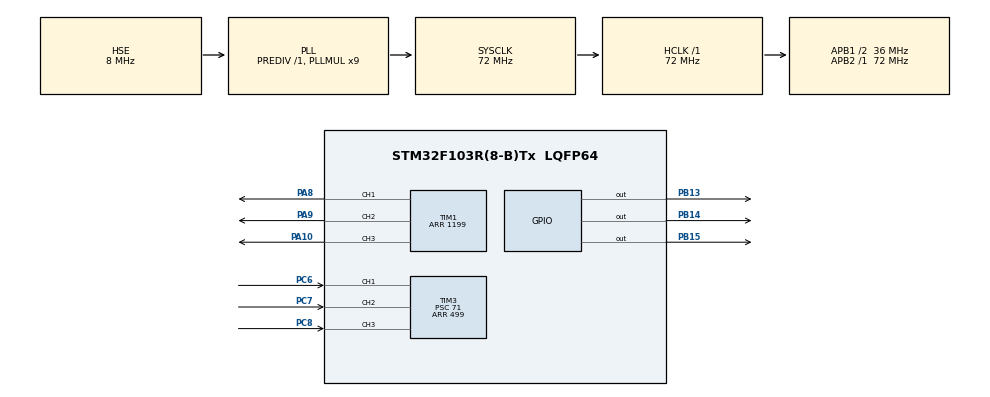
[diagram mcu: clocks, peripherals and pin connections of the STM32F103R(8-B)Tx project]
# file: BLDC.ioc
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Mcu.Family=STM32F1
Mcu.Name=STM32F103R(8-B)Tx
Mcu.Package=LQFP64
NVIC.PriorityGroup=NVIC_PRIORITYGROUP_4
NVIC.TIM3_IRQn=true\:0\:0\:false\:false\:true\:true\:true
PA10.Signal=S_TIM1_CH3
PA13.Mode=Serial_Wire
PA13.Signal=SYS_JTMS-SWDIO
PA14.Mode=Serial_Wire
PA14.Signal=SYS_JTCK-SWCLK
PA8.Signal=S_TIM1_CH1
PA9.Signal=S_TIM1_CH2
PB13.GPIO_PuPd=GPIO_PULLUP
PB13.GPIO_Speed=GPIO_SPEED_FREQ_MEDIUM
PB13.PinState=GPIO_PIN_SET
PB13.Signal=GPIO_Output
PB14.GPIO_PuPd=GPIO_PULLUP
PB14.GPIO_Speed=GPIO_SPEED_FREQ_MEDIUM
PB14.PinState=GPIO_PIN_SET
PB14.Signal=GPIO_Output
PB15.GPIO_PuPd=GPIO_PULLUP
PB15.GPIO_Speed=GPIO_SPEED_FREQ_MEDIUM
PB15.PinState=GPIO_PIN_SET
PB15.Signal=GPIO_Output
PC6.Signal=S_TIM3_CH1
PC7.Signal=S_TIM3_CH2
PC8.Signal=S_TIM3_CH3
PD0-OSC_IN.Mode=HSE-External-Oscillator
PD0-OSC_IN.Signal=RCC_OSC_IN
PD1-OSC_OUT.Mode=HSE-External-Oscillator
PD1-OSC_OUT.Signal=RCC_OSC_OUT
ProjectManager.HeapSize=0x200
ProjectManager.StackSize=0x400
ProjectManager.TargetToolchain=MDK-ARM V5.27
RCC.AHBFreq_Value=72000000
RCC.APB1CLKDivider=RCC_HCLK_DIV2
RCC.APB1Freq_Value=36000000
RCC.APB1TimFreq_Value=72000000
RCC.APB2Freq_Value=72000000
RCC.APB2TimFreq_Value=72000000
RCC.HCLKFreq_Value=72000000
RCC.PLLMUL=RCC_PLL_MUL9
RCC.PLLSourceVirtual=RCC_PLLSOURCE_HSE
RCC.SYSCLKFreq_VALUE=72000000
RCC.SYSCLKSource=RCC_SYSCLKSOURCE_PLLCLK
RCC.USBFreq_Value=72000000
SH.S_TIM1_CH1.0=TIM1_CH1,PWM Generation1 CH1
SH.S_TIM1_CH2.0=TIM1_CH2,PWM Generation2 CH2
SH.S_TIM1_CH3.0=TIM1_CH3,PWM Generation3 CH3
SH.S_TIM3_CH1.0=TIM3_CH1,Input_Capture1_from_TI1
SH.S_TIM3_CH2.0=TIM3_CH2,Input_Capture2_from_TI2
SH.S_TIM3_CH3.0=TIM3_CH3,Input_Capture3_from_TI3
TIM1.Channel-PWM\ Generation1\ CH1=TIM_CHANNEL_1
TIM1.Channel-PWM\ Generation2\ CH2=TIM_CHANNEL_2
TIM1.Channel-PWM\ Generation3\ CH3=TIM_CHANNEL_3
TIM1.Period=1199
TIM1.Pulse-PWM\ Generation1\ CH1=500
TIM1.Pulse-PWM\ Generation2\ CH2=500
TIM1.Pulse-PWM\ Generation3\ CH3=500
TIM3.Channel-Input_Capture1_from_TI1=TIM_CHANNEL_1
TIM3.Channel-Input_Capture2_from_TI2=TIM_CHANNEL_2
TIM3.Channel-Input_Capture3_from_TI3=TIM_CHANNEL_3
TIM3.ICFilter_CH1=2
TIM3.ICFilter_CH2=2
TIM3.ICFilter_CH3=2
TIM3.Period=499
TIM3.Prescaler=71
VP_TIM1_VS_ClockSourceINT.Mode=Internal
VP_TIM3_VS_ClockSourceINT.Mode=Internal
VP_TIM3_VS_XOR.Mode=XOR_enable
board=custom

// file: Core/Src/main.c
/* USER CODE BEGIN Header */
/**
  ******************************************************************************
  * @file           : main.c
  * @brief          : Main program body
  ******************************************************************************
  * @attention
  *
  * <h2><center>&copy; Copyright (c) 2021 STMicroelectronics.
  * All rights reserved.</center></h2>
  *
  * This software component is licensed by ST under BSD 3-Clause license,
  * the "License"; You may not use this file except in compliance with the
  * License. You may obtain a copy of the License at:
  *                        opensource.org/licenses/BSD-3-Clause
  *
  ******************************************************************************
  */
/* USER CODE END Header */
#include "main.h"
#include "tim.h"
#include "gpio.h"

/* USER CODE BEGIN Includes */
#include "bldc.h"
/* USER CODE END Includes */

void SystemClock_Config(void);

int main(void)
{
  /* USER CODE BEGIN 1 */
  uint32_t i;
  /* USER CODE END 1 */

  /* MCU Configuration--------------------------------------------------------*/

  /* Reset of all peripherals, Initializes the Flash interface and the Systick. */
  HAL_Init();

  /* Configure the system clock */
  SystemClock_Config();

  /* Initialize all configured peripherals */
  MX_GPIO_Init();
  MX_TIM1_Init();
  MX_TIM3_Init();

  /* Infinite loop */
  while (1)
  {

    /* USER CODE BEGIN 3 */
	// forwards 3s
    i = HAL_GetTick();
    while (HAL_GetTick() - i < 3000)
    {
      BldcMove(0);
    }
	// reverse 3s
//    i = HAL_GetTick();
//    while (HAL_GetTick() - i < 3000)
//    {
//      BldcMove(1);
//    }
  }
  /* USER CODE END 3 */
}

void SystemClock_Config(void)
{
  RCC_OscInitTypeDef RCC_OscInitStruct = {0};
  RCC_ClkInitTypeDef RCC_ClkInitStruct = {0};

  /** Initializes the RCC Oscillators according to the specified parameters
  * in the RCC_OscInitTypeDef structure.
  */
  RCC_OscInitStruct.OscillatorType = RCC_OSCILLATORTYPE_HSE;
  RCC_OscInitStruct.HSEState = RCC_HSE_ON;
  RCC_OscInitStruct.HSEPredivValue = RCC_HSE_PREDIV_DIV1;
  RCC_OscInitStruct.HSIState = RCC_HSI_ON;
  RCC_OscInitStruct.PLL.PLLState = RCC_PLL_ON;
  RCC_OscInitStruct.PLL.PLLSource = RCC_PLLSOURCE_HSE;
  RCC_OscInitStruct.PLL.PLLMUL = RCC_PLL_MUL9;
  if (HAL_RCC_OscConfig(&RCC_OscInitStruct) != HAL_OK)
  {
    Error_Handler();
  }
  /** Initializes the CPU, AHB and APB buses clocks
  */
  RCC_ClkInitStruct.ClockType = RCC_CLOCKTYPE_HCLK|RCC_CLOCKTYPE_SYSCLK
                              |RCC_CLOCKTYPE_PCLK1|RCC_CLOCKTYPE_PCLK2;
  RCC_ClkInitStruct.SYSCLKSource = RCC_SYSCLKSOURCE_PLLCLK;
  RCC_ClkInitStruct.AHBCLKDivider = RCC_SYSCLK_DIV1;
  RCC_ClkInitStruct.APB1CLKDivider = RCC_HCLK_DIV2;
  RCC_ClkInitStruct.APB2CLKDivider = RCC_HCLK_DIV1;

  if (HAL_RCC_ClockConfig(&RCC_ClkInitStruct, FLASH_LATENCY_2) != HAL_OK)
  {
    Error_Handler();
  }
}

void Error_Handler(void)
{
  __disable_irq();
  while (1)
  {
  }
}

/************************ (C) COPYRIGHT STMicroelectronics *****END OF FILE****/
